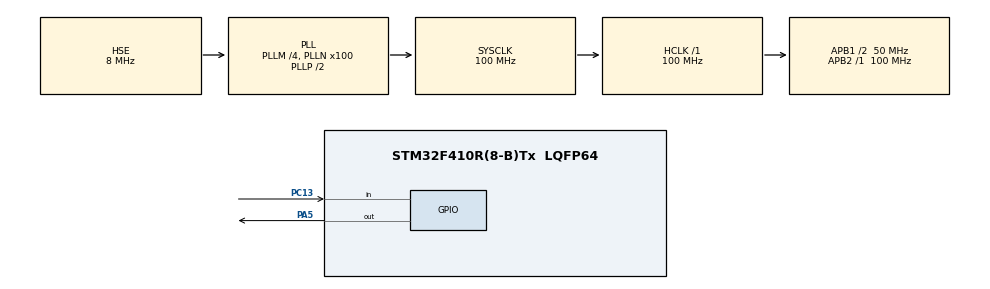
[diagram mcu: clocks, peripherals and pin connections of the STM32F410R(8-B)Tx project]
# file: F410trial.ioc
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Mcu.Family=STM32F4
Mcu.Name=STM32F410R(8-B)Tx
Mcu.Package=LQFP64
NVIC.PriorityGroup=NVIC_PRIORITYGROUP_4
PA13.Mode=Serial_Wire
PA13.Signal=SYS_JTMS-SWDIO
PA14.Mode=Serial_Wire
PA14.Signal=SYS_JTCK-SWCLK
PA5.Signal=GPIO_Output
PC13-ANTI_TAMP.Signal=GPIO_Input
PH0\ -\ OSC_IN.Mode=HSE-External-Clock-Source
PH0\ -\ OSC_IN.Signal=RCC_OSC_IN
PH1\ -\ OSC_OUT.Mode=HSE-External-Clock-Source
PH1\ -\ OSC_OUT.Signal=RCC_OSC_OUT
ProjectManager.HeapSize=0x200
ProjectManager.StackSize=0x400
ProjectManager.TargetToolchain=MDK-ARM V5.32
RCC.48MHZClocksFreq_Value=50000000
RCC.AHBFreq_Value=100000000
RCC.APB1CLKDivider=RCC_HCLK_DIV2
RCC.APB1Freq_Value=50000000
RCC.APB1TimFreq_Value=100000000
RCC.APB2Freq_Value=100000000
RCC.APB2TimFreq_Value=100000000
RCC.CortexFreq_Value=100000000
RCC.HCLKFreq_Value=100000000
RCC.HSE_VALUE=8000000
RCC.HSI_VALUE=16000000
RCC.LSE_VALUE=32768
RCC.PLLM=4
RCC.PLLN=100
RCC.PLLSourceVirtual=RCC_PLLSOURCE_HSE
RCC.SYSCLKFreq_VALUE=100000000
RCC.SYSCLKSource=RCC_SYSCLKSOURCE_PLLCLK
RCC.VCOOutputFreq_Value=200000000
board=custom

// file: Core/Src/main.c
/* USER CODE BEGIN Header */
/**
  * @file           : main.c
  * @brief          : CAT12A - On-board LED Bring-Up
  */
/* USER CODE END Header */
#include "main.h"

void SystemClock_Config(void);
static void MX_GPIO_Init(void);

int main(void)
{
  HAL_Init();
  SystemClock_Config();
  MX_GPIO_Init();
  /* USER CODE BEGIN 2 */
  /* PA5 drives the LED output. */
  /* USER CODE END 2 */

  /* Infinite loop */
  /* USER CODE BEGIN WHILE */
  while (1)
  {
    HAL_GPIO_TogglePin(GPIOA, GPIO_PIN_5);
    HAL_Delay(500);
    /* USER CODE END WHILE */
  }
}

void SystemClock_Config(void)
{
  RCC_OscInitTypeDef RCC_OscInitStruct = {0};
  RCC_ClkInitTypeDef RCC_ClkInitStruct = {0};
  __HAL_RCC_PWR_CLK_ENABLE();
  __HAL_PWR_VOLTAGESCALING_CONFIG(PWR_REGULATOR_VOLTAGE_SCALE1);
  RCC_OscInitStruct.OscillatorType = RCC_OSCILLATORTYPE_HSE;
  RCC_OscInitStruct.HSEState = RCC_HSE_BYPASS;
  RCC_OscInitStruct.PLL.PLLState = RCC_PLL_ON;
  RCC_OscInitStruct.PLL.PLLSource = RCC_PLLSOURCE_HSE;
  RCC_OscInitStruct.PLL.PLLM = 4;
  RCC_OscInitStruct.PLL.PLLN = 100;
  RCC_OscInitStruct.PLL.PLLP = RCC_PLLP_DIV2;
  RCC_OscInitStruct.PLL.PLLQ = 4;
  RCC_OscInitStruct.PLL.PLLR = 2;
  if (HAL_RCC_OscConfig(&RCC_OscInitStruct) != HAL_OK) Error_Handler();
  RCC_ClkInitStruct.ClockType = RCC_CLOCKTYPE_HCLK|RCC_CLOCKTYPE_SYSCLK|RCC_CLOCKTYPE_PCLK1|RCC_CLOCKTYPE_PCLK2;
  RCC_ClkInitStruct.SYSCLKSource = RCC_SYSCLKSOURCE_PLLCLK;
  RCC_ClkInitStruct.AHBCLKDivider = RCC_SYSCLK_DIV1;
  RCC_ClkInitStruct.APB1CLKDivider = RCC_HCLK_DIV2;
  RCC_ClkInitStruct.APB2CLKDivider = RCC_HCLK_DIV1;
  if (HAL_RCC_ClockConfig(&RCC_ClkInitStruct, FLASH_LATENCY_3) != HAL_OK) Error_Handler();
}

static void MX_GPIO_Init(void)
{
  GPIO_InitTypeDef GPIO_InitStruct = {0};
  __HAL_RCC_GPIOA_CLK_ENABLE();
  HAL_GPIO_WritePin(GPIOA, GPIO_PIN_5, GPIO_PIN_RESET);
  GPIO_InitStruct.Pin = GPIO_PIN_5;
  GPIO_InitStruct.Mode = GPIO_MODE_OUTPUT_PP;
  GPIO_InitStruct.Pull = GPIO_NOPULL;
  GPIO_InitStruct.Speed = GPIO_SPEED_FREQ_LOW;
  HAL_GPIO_Init(GPIOA, &GPIO_InitStruct);
}

void Error_Handler(void)
{
  __disable_irq();
  while (1) {}
}
